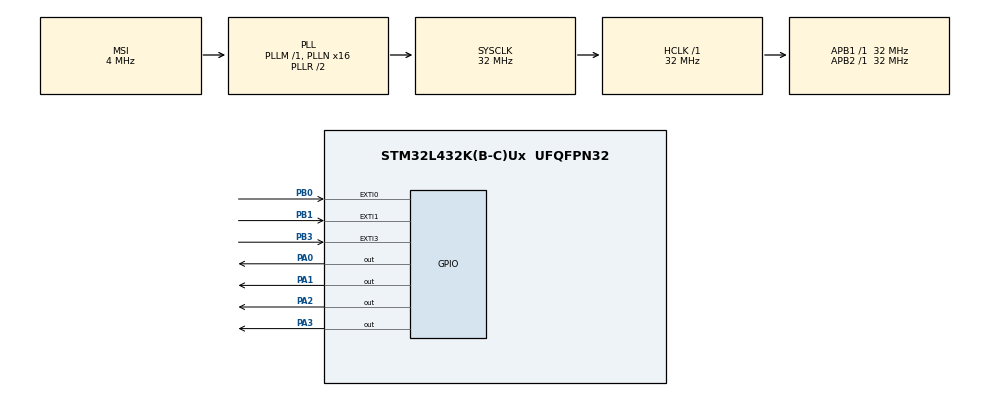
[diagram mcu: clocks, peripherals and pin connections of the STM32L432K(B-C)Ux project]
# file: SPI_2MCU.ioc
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Mcu.Family=STM32L4
Mcu.Name=STM32L432K(B-C)Ux
Mcu.Package=UFQFPN32
NVIC.PriorityGroup=NVIC_PRIORITYGROUP_4
PA0.Signal=GPIO_Output
PA1.Signal=GPIO_Output
PA2.Signal=GPIO_Output
PA3.Signal=GPIO_Output
PB0.Signal=GPXTI0
PB1.Signal=GPXTI1
PB3\ (JTDO-TRACESWO).Signal=GPXTI3
PB4\ (NJTRST).Signal=SPI1_MISO
PB5.Signal=SPI1_MOSI
ProjectManager.HeapSize=0x200
ProjectManager.StackSize=0x400
ProjectManager.TargetToolchain=STM32CubeIDE
RCC.ADCFreq_Value=16000000
RCC.AHBFreq_Value=32000000
RCC.APB1Freq_Value=32000000
RCC.APB1TimFreq_Value=32000000
RCC.APB2Freq_Value=32000000
RCC.APB2TimFreq_Value=32000000
RCC.CortexFreq_Value=32000000
RCC.HCLKFreq_Value=32000000
RCC.HSE_VALUE=8000000
RCC.HSI48_VALUE=48000000
RCC.HSI_VALUE=16000000
RCC.LSE_VALUE=32768
RCC.MSI_VALUE=4000000
RCC.PLLN=16
RCC.SYSCLKFreq_VALUE=32000000
RCC.SYSCLKSource=RCC_SYSCLKSOURCE_PLLCLK
RCC.USBFreq_Value=16000000
RCC.VCOOutputFreq_Value=64000000
board=custom

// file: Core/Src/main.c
/* USER CODE BEGIN Header */
/**
  ******************************************************************************
  * @file           : main.c
  * @brief          : Main program body
  ******************************************************************************
  * @attention
  *
  * Copyright (c) 2022 STMicroelectronics.
  * All rights reserved.
  *
  * This software is licensed under terms that can be found in the LICENSE file
  * in the root directory of this software component.
  * If no LICENSE file comes with this software, it is provided AS-IS.
  *
  ******************************************************************************
  */
/* USER CODE END Header */
#include "main.h"

/* USER CODE BEGIN PV */
typedef enum
{
	DATA_RCV_CMP = 0,
	DATA_NO_RCV,
	DATA_TX_CMP,
	DATA_NO_TX
}FLAG_t;

typedef enum
{
	LEFT = 0,
	RIGTH,
	MIDDLE,
	INVALID_DIRECTION
}direction_t;

typedef enum
{
	STOP = 0,
	RUN,
	INVALID_STATE
}status_t;

direction_t direction = INVALID_DIRECTION;
status_t state = INVALID_STATE;
uint8_t count_yellow_input = 0;
/* USER CODE END PV */

void SystemClock_Config(void);
static void MX_GPIO_Init(void);

/* USER CODE BEGIN 0 */

void toggle_ligth(direction_t dir);
/* USER CODE END 0 */

int main(void)
{

  /* MCU Configuration--------------------------------------------------------*/

  /* Reset of all peripherals, Initializes the Flash interface and the Systick. */
  HAL_Init();

  /* Configure the system clock */
  SystemClock_Config();

  /* Initialize all configured peripherals */
  MX_GPIO_Init();

  /* Infinite loop */
  while (1)
  {

	  if(state == RUN)
	  {
		switch(direction)
		{
		case LEFT:
			toggle_ligth(LEFT);
			break;
		case RIGTH:
			toggle_ligth(RIGTH);
			break;
		case MIDDLE:
			toggle_ligth(MIDDLE);
			break;

		default:
			// Report invalid direction
			break;
		}
	  }
	  else if(state == STOP)
	  {
		  HAL_GPIO_WritePin(GPIOA, (GPIO_PIN_0 | GPIO_PIN_1 | GPIO_PIN_3 | GPIO_PIN_4), GPIO_PIN_RESET);
	  }

  }
}

void SystemClock_Config(void)
{
  RCC_OscInitTypeDef RCC_OscInitStruct = {0};
  RCC_ClkInitTypeDef RCC_ClkInitStruct = {0};

  /** Configure the main internal regulator output voltage
  */
  if (HAL_PWREx_ControlVoltageScaling(PWR_REGULATOR_VOLTAGE_SCALE1) != HAL_OK)
  {
    Error_Handler();
  }

  /** Initializes the RCC Oscillators according to the specified parameters
  * in the RCC_OscInitTypeDef structure.
  */
  RCC_OscInitStruct.OscillatorType = RCC_OSCILLATORTYPE_MSI;
  RCC_OscInitStruct.MSIState = RCC_MSI_ON;
  RCC_OscInitStruct.MSICalibrationValue = 0;
  RCC_OscInitStruct.MSIClockRange = RCC_MSIRANGE_6;
  RCC_OscInitStruct.PLL.PLLState = RCC_PLL_ON;
  RCC_OscInitStruct.PLL.PLLSource = RCC_PLLSOURCE_MSI;
  RCC_OscInitStruct.PLL.PLLM = 1;
  RCC_OscInitStruct.PLL.PLLN = 16;
  RCC_OscInitStruct.PLL.PLLP = RCC_PLLP_DIV7;
  RCC_OscInitStruct.PLL.PLLQ = RCC_PLLQ_DIV2;
  RCC_OscInitStruct.PLL.PLLR = RCC_PLLR_DIV2;
  if (HAL_RCC_OscConfig(&RCC_OscInitStruct) != HAL_OK)
  {
    Error_Handler();
  }

  /** Initializes the CPU, AHB and APB buses clocks
  */
  RCC_ClkInitStruct.ClockType = RCC_CLOCKTYPE_HCLK|RCC_CLOCKTYPE_SYSCLK
                              |RCC_CLOCKTYPE_PCLK1|RCC_CLOCKTYPE_PCLK2;
  RCC_ClkInitStruct.SYSCLKSource = RCC_SYSCLKSOURCE_PLLCLK;
  RCC_ClkInitStruct.AHBCLKDivider = RCC_SYSCLK_DIV1;
  RCC_ClkInitStruct.APB1CLKDivider = RCC_HCLK_DIV1;
  RCC_ClkInitStruct.APB2CLKDivider = RCC_HCLK_DIV1;

  if (HAL_RCC_ClockConfig(&RCC_ClkInitStruct, FLASH_LATENCY_1) != HAL_OK)
  {
    Error_Handler();
  }
}

static void MX_GPIO_Init(void)
{
  GPIO_InitTypeDef GPIO_InitStruct = {0};

  /* GPIO Ports Clock Enable */
  __HAL_RCC_GPIOA_CLK_ENABLE();
  __HAL_RCC_GPIOB_CLK_ENABLE();

  /*Configure GPIO pin Output Level */
  HAL_GPIO_WritePin(GPIOA, GPIO_PIN_0|GPIO_PIN_1|GPIO_PIN_2|GPIO_PIN_3|GPIO_PIN_4, GPIO_PIN_RESET);

  /*Configure GPIO pins : PA0 PA1 PA2 PA3 */
  GPIO_InitStruct.Pin = GPIO_PIN_0|GPIO_PIN_1|GPIO_PIN_2|GPIO_PIN_3|GPIO_PIN_4;
  GPIO_InitStruct.Mode = GPIO_MODE_OUTPUT_PP;
  GPIO_InitStruct.Pull = GPIO_NOPULL;
  GPIO_InitStruct.Speed = GPIO_SPEED_FREQ_LOW;
  HAL_GPIO_Init(GPIOA, &GPIO_InitStruct);

  /*Configure GPIO pins : PB0 PB1 PB3 */
  GPIO_InitStruct.Pin = GPIO_PIN_0|GPIO_PIN_1|GPIO_PIN_3;
  GPIO_InitStruct.Mode = GPIO_MODE_IT_FALLING;
  GPIO_InitStruct.Pull = GPIO_NOPULL;
  HAL_GPIO_Init(GPIOB, &GPIO_InitStruct);

  /*Configure GPIO pins : PB4 PB5 */
  GPIO_InitStruct.Pin = GPIO_PIN_4|GPIO_PIN_5;
  GPIO_InitStruct.Mode = GPIO_MODE_AF_PP;
  GPIO_InitStruct.Pull = GPIO_NOPULL;
  GPIO_InitStruct.Speed = GPIO_SPEED_FREQ_VERY_HIGH;
  GPIO_InitStruct.Alternate = GPIO_AF5_SPI1;
  HAL_GPIO_Init(GPIOB, &GPIO_InitStruct);

  HAL_NVIC_SetPriority(EXTI0_IRQn, 0, 0);
  HAL_NVIC_EnableIRQ(EXTI0_IRQn);
  HAL_NVIC_SetPriority(EXTI1_IRQn, 0, 0);
  HAL_NVIC_EnableIRQ(EXTI1_IRQn);
  HAL_NVIC_SetPriority(EXTI3_IRQn, 0, 0);
  HAL_NVIC_EnableIRQ(EXTI3_IRQn);

}

/* USER CODE BEGIN 4 */

void toggle_ligth(direction_t dir)
{
	if(dir == LEFT)
	{
		HAL_GPIO_WritePin(GPIOA, GPIO_PIN_4, GPIO_PIN_SET);
		HAL_Delay(100);
		HAL_GPIO_WritePin(GPIOA, GPIO_PIN_4, GPIO_PIN_RESET);
		HAL_Delay(100);

		HAL_GPIO_WritePin(GPIOA, GPIO_PIN_3, GPIO_PIN_SET);
		HAL_Delay(100);
		HAL_GPIO_WritePin(GPIOA, GPIO_PIN_3, GPIO_PIN_RESET);

		HAL_Delay(100);

		HAL_GPIO_WritePin(GPIOA, GPIO_PIN_1, GPIO_PIN_SET);
		HAL_Delay(100);
		HAL_GPIO_WritePin(GPIOA, GPIO_PIN_1, GPIO_PIN_RESET);

		HAL_Delay(100);
		HAL_GPIO_WritePin(GPIOA, GPIO_PIN_0, GPIO_PIN_SET);
		HAL_Delay(100);
		HAL_GPIO_WritePin(GPIOA, GPIO_PIN_0, GPIO_PIN_RESET);
		HAL_Delay(100);
	}
	else if(dir == RIGTH)
	{
		HAL_GPIO_WritePin(GPIOA, GPIO_PIN_0, GPIO_PIN_SET);
		HAL_Delay(100);
		HAL_GPIO_WritePin(GPIOA, GPIO_PIN_0, GPIO_PIN_RESET);
		HAL_Delay(100);

		HAL_GPIO_WritePin(GPIOA, GPIO_PIN_1, GPIO_PIN_SET);
		HAL_Delay(100);
		HAL_GPIO_WritePin(GPIOA, GPIO_PIN_1, GPIO_PIN_RESET);

		HAL_Delay(100);

		HAL_GPIO_WritePin(GPIOA, GPIO_PIN_3, GPIO_PIN_SET);
		HAL_Delay(100);
		HAL_GPIO_WritePin(GPIOA, GPIO_PIN_3, GPIO_PIN_RESET);

		HAL_Delay(100);
		HAL_GPIO_WritePin(GPIOA, GPIO_PIN_4, GPIO_PIN_SET);
		HAL_Delay(100);
		HAL_GPIO_WritePin(GPIOA, GPIO_PIN_4, GPIO_PIN_RESET);
		HAL_Delay(100);
	}
	else if(dir == MIDDLE)
	{
		HAL_GPIO_WritePin(GPIOA, GPIO_PIN_1, GPIO_PIN_SET);
		HAL_GPIO_WritePin(GPIOA, GPIO_PIN_3, GPIO_PIN_SET);
		HAL_Delay(100);
		HAL_GPIO_WritePin(GPIOA, GPIO_PIN_1, GPIO_PIN_RESET);
		HAL_GPIO_WritePin(GPIOA, GPIO_PIN_3, GPIO_PIN_RESET);
		HAL_Delay(100);

		HAL_GPIO_WritePin(GPIOA, GPIO_PIN_4, GPIO_PIN_SET);
		HAL_GPIO_WritePin(GPIOA, GPIO_PIN_0, GPIO_PIN_SET);
		HAL_Delay(100);
		HAL_GPIO_WritePin(GPIOA, GPIO_PIN_4, GPIO_PIN_RESET);
		HAL_GPIO_WritePin(GPIOA, GPIO_PIN_0, GPIO_PIN_RESET);
		HAL_Delay(100);

	}
}

/**
  * @brief This function handles EXTI line[0:3] interrupts.
  */
// Yellow button
void EXTI0_IRQHandler(void)
{
  HAL_GPIO_EXTI_IRQHandler(GPIO_PIN_0);
}

// Red button
void EXTI1_IRQHandler(void)
{
  HAL_GPIO_EXTI_IRQHandler(GPIO_PIN_1);
}

// Green button
void EXTI3_IRQHandler(void)
{
  HAL_GPIO_EXTI_IRQHandler(GPIO_PIN_3);
}

void HAL_GPIO_EXTI_Callback(uint16_t GPIO_Pin)
{
	if(GPIO_Pin == GPIO_PIN_0) // Yellow Button
	{
		if(!(GPIOB->IDR & GPIO_PIN_0))
		{
			if(state == RUN)
			{
				count_yellow_input++;
				if(count_yellow_input == 1)
				{
					direction = RIGTH;
				}
				else if(count_yellow_input == 2)
				{
					direction = MIDDLE;
				}
				else if(count_yellow_input == 3)
				{
					direction = LEFT;
				}

				if(count_yellow_input == 4)
				{
					count_yellow_input = 0;
				}
			}
		}
	}
	else if(GPIO_Pin == GPIO_PIN_1) // Red button
	{
		if(!(GPIOB->IDR & GPIO_PIN_1))
		{
			state = STOP;
			count_yellow_input = 0;
		}
	}
	else if(GPIO_Pin == GPIO_PIN_3) // Green button
	{
		if(!(GPIOB->IDR & GPIO_PIN_3))
		{
			state = RUN;
			direction = LEFT;
			count_yellow_input = 0;
		}
	}
}

/* USER CODE END 4 */

void Error_Handler(void)
{
  __disable_irq();
  while (1)
  {
  }
}
